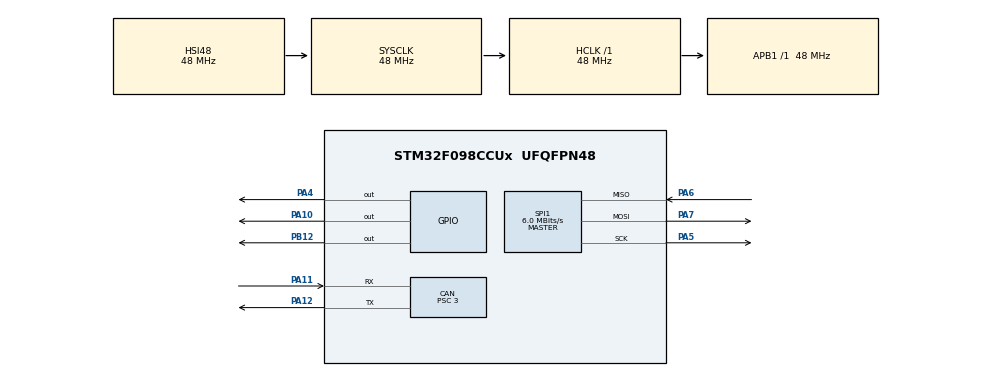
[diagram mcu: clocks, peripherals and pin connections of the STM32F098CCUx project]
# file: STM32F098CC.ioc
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CAN.BS1=CAN_BS1_13TQ
CAN.BS2=CAN_BS2_2TQ
CAN.CalculateTimeQuantum=62.5
CAN.Mode=CAN_MODE_SILENT_LOOPBACK
CAN.Prescaler=3
CAN.SJW=CAN_SJW_1TQ
Dma.Request0=SPI1_RX
Dma.SPI1_RX.0.Direction=DMA_PERIPH_TO_MEMORY
Dma.SPI1_RX.0.Instance=DMA1_Channel2
Dma.SPI1_RX.0.MemDataAlignment=DMA_MDATAALIGN_BYTE
Dma.SPI1_RX.0.MemInc=DMA_MINC_ENABLE
Dma.SPI1_RX.0.Mode=DMA_NORMAL
Dma.SPI1_RX.0.PeriphDataAlignment=DMA_PDATAALIGN_BYTE
Dma.SPI1_RX.0.PeriphInc=DMA_PINC_DISABLE
Dma.SPI1_RX.0.Priority=DMA_PRIORITY_LOW
Mcu.Family=STM32F0
Mcu.Name=STM32F098CCUx
Mcu.Package=UFQFPN48
NVIC.DMA1_Ch2_3_DMA2_Ch1_2_IRQn=true\:0\:0\:false\:false\:true\:false
PA10.Signal=GPIO_Output
PA11.Mode=Master
PA11.Signal=CAN_RX
PA12.Mode=Master
PA12.Signal=CAN_TX
PA4.Signal=GPIO_Output
PA5.Mode=Full_Duplex_Master
PA5.Signal=SPI1_SCK
PA6.Mode=Full_Duplex_Master
PA6.Signal=SPI1_MISO
PA7.Mode=Full_Duplex_Master
PA7.Signal=SPI1_MOSI
PB12.Signal=GPIO_Output
ProjectManager.HeapSize=0x200
ProjectManager.StackSize=0x400
ProjectManager.TargetToolchain=TrueSTUDIO
RCC.AHBFreq_Value=48000000
RCC.APB1Freq_Value=48000000
RCC.APB1TimFreq_Value=48000000
RCC.HCLKFreq_Value=48000000
RCC.PLLDivider=RCC_PREDIV_DIV2
RCC.PLLSourceVirtual=RCC_PLLSOURCE_HSI48
RCC.SYSCLKFreq_VALUE=48000000
RCC.SYSCLKSource=RCC_SYSCLKSOURCE_HSI48
SPI1.BaudRatePrescaler=SPI_BAUDRATEPRESCALER_8
SPI1.CLKPhase=SPI_PHASE_2EDGE
SPI1.CLKPolarity=SPI_POLARITY_HIGH
SPI1.CalculateBaudRate=6.0 MBits/s
SPI1.DataSize=SPI_DATASIZE_8BIT
SPI1.Direction=SPI_DIRECTION_2LINES
SPI1.Mode=SPI_MODE_MASTER
SPI1.VirtualType=VM_MASTER
TIM1.Period=65535
TIM2.Period=4294967295
VP_TIM1_VS_ClockSourceINT.Mode=Internal
VP_TIM2_VS_ClockSourceINT.Mode=Internal
board=custom

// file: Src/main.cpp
/**
  ******************************************************************************
  * @file           : main.c
  * @brief          : Main program body
  ******************************************************************************
  ** This notice applies to any and all portions of this file
  * that are not between comment pairs USER CODE BEGIN and
  * USER CODE END. Other portions of this file, whether
  * inserted by the user or by software development tools
  * are owned by their respective copyright owners.
  *
  * COPYRIGHT(c) 2018 STMicroelectronics
  *
  * Redistribution and use in source and binary forms, with or without modification,
  * are permitted provided that the following conditions are met:
  *   1. Redistributions of source code must retain the above copyright notice,
  *      this list of conditions and the following disclaimer.
  *   2. Redistributions in binary form must reproduce the above copyright notice,
  *      this list of conditions and the following disclaimer in the documentation
  *      and/or other materials provided with the distribution.
  *   3. Neither the name of STMicroelectronics nor the names of its contributors
  *      may be used to endorse or promote products derived from this software
  *      without specific prior written permission.
  *
  * THIS SOFTWARE IS PROVIDED BY THE COPYRIGHT HOLDERS AND CONTRIBUTORS "AS IS"
  * AND ANY EXPRESS OR IMPLIED WARRANTIES, INCLUDING, BUT NOT LIMITED TO, THE
  * IMPLIED WARRANTIES OF MERCHANTABILITY AND FITNESS FOR A PARTICULAR PURPOSE ARE
  * DISCLAIMED. IN NO EVENT SHALL THE COPYRIGHT HOLDER OR CONTRIBUTORS BE LIABLE
  * FOR ANY DIRECT, INDIRECT, INCIDENTAL, SPECIAL, EXEMPLARY, OR CONSEQUENTIAL
  * DAMAGES (INCLUDING, BUT NOT LIMITED TO, PROCUREMENT OF SUBSTITUTE GOODS OR
  * SERVICES; LOSS OF USE, DATA, OR PROFITS; OR BUSINESS INTERRUPTION) HOWEVER
  * CAUSED AND ON ANY THEORY OF LIABILITY, WHETHER IN CONTRACT, STRICT LIABILITY,
  * OR TORT (INCLUDING NEGLIGENCE OR OTHERWISE) ARISING IN ANY WAY OUT OF THE USE
  * OF THIS SOFTWARE, EVEN IF ADVISED OF THE POSSIBILITY OF SUCH DAMAGE.
  *
  ******************************************************************************
  */
#include "main.h"
#include "stm32f0xx_hal.h"
#include "stm32f0xx.h"
#include "can.h"
#include "dma.h"
#include "spi.h"
#include "tim.h"
#include "gpio.h"

/* USER CODE BEGIN Includes */
#include "chip.h"
#include <iostream>
#include <cstdlib>
#include <unistd.h>
#include <uavcan/uavcan.hpp>

/* USER CODE END Includes */

/* USER CODE BEGIN PV */
/* Private variables ---------------------------------------------------------*/

/* USER CODE END PV */

void SystemClock_Config(void);

/* USER CODE BEGIN PFP */
/* Private function prototypes -----------------------------------------------*/

/* USER CODE END PFP */

int main(void)
{

  /* MCU Configuration----------------------------------------------------------*/

  /* Reset of all peripherals, Initializes the Flash interface and the Systick. */
  HAL_Init();

  /* Configure the system clock */
  SystemClock_Config();

  /* Initialize all configured peripherals */
  MX_GPIO_Init();
  MX_DMA_Init();
  MX_SPI1_Init();
  MX_CAN_Init();
  MX_TIM1_Init();
  MX_TIM2_Init();

  /* Infinite loop */
  /* USER CODE BEGIN WHILE */
  while (1)
  {
	  HAL_Delay(100);
  /* USER CODE END WHILE */

  }

}

void SystemClock_Config(void)
{

  RCC_OscInitTypeDef RCC_OscInitStruct;
  RCC_ClkInitTypeDef RCC_ClkInitStruct;

    /**Initializes the CPU, AHB and APB busses clocks
    */
  RCC_OscInitStruct.OscillatorType = RCC_OSCILLATORTYPE_HSI48;
  RCC_OscInitStruct.HSI48State = RCC_HSI48_ON;
  RCC_OscInitStruct.PLL.PLLState = RCC_PLL_NONE;
  if (HAL_RCC_OscConfig(&RCC_OscInitStruct) != HAL_OK)
  {
    _Error_Handler(__FILE__, __LINE__);
  }
    /**Initializes the CPU, AHB and APB busses clocks
    */
  RCC_ClkInitStruct.ClockType = RCC_CLOCKTYPE_HCLK|RCC_CLOCKTYPE_SYSCLK
                              |RCC_CLOCKTYPE_PCLK1;
  RCC_ClkInitStruct.SYSCLKSource = RCC_SYSCLKSOURCE_HSI48;
  RCC_ClkInitStruct.AHBCLKDivider = RCC_SYSCLK_DIV1;
  RCC_ClkInitStruct.APB1CLKDivider = RCC_HCLK_DIV1;

  if (HAL_RCC_ClockConfig(&RCC_ClkInitStruct, FLASH_LATENCY_1) != HAL_OK)
  {
    _Error_Handler(__FILE__, __LINE__);
  }

    /**Configure the Systick interrupt time
    */
  HAL_SYSTICK_Config(HAL_RCC_GetHCLKFreq()/1000);

    /**Configure the Systick
    */
  HAL_SYSTICK_CLKSourceConfig(SYSTICK_CLKSOURCE_HCLK);

  /* SysTick_IRQn interrupt configuration */
  HAL_NVIC_SetPriority(SysTick_IRQn, 0, 0);
}

void _Error_Handler(char *file, int line)
{
  while(1)
  {
  }
}

/************************ (C) COPYRIGHT STMicroelectronics *****END OF FILE****/
